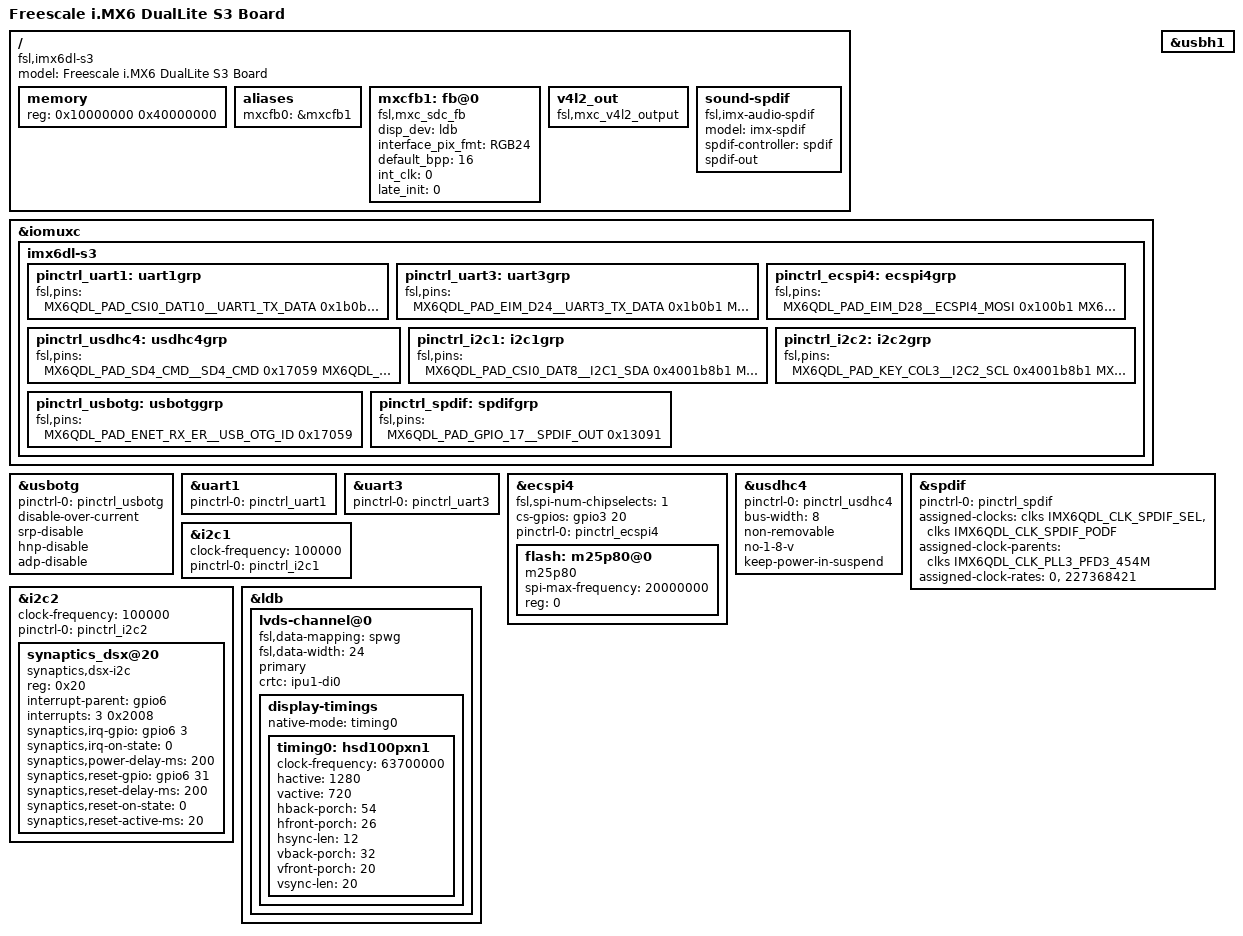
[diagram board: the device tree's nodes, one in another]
/*
 * Copyright (C) 2013 Freescale Semiconductor, Inc.
 *
 * This program is free software; you can redistribute it and/or modify
 * it under the terms of the GNU General Public License version 2 as
 * published by the Free Software Foundation.
 */

/dts-v1/;
#include "imx6dl.dtsi"
#include <dt-bindings/input/input.h>

/ {
	model = "Freescale i.MX6 DualLite S3 Board";
	compatible = "fsl,imx6dl-s3", "fsl,imx6dl";
	memory {
		reg = <0x10000000 0x40000000>;
	};
	
	aliases {
		mxcfb0 = &mxcfb1;
	};	
	mxcfb1: fb@0 {
		compatible = "fsl,mxc_sdc_fb";
		disp_dev = "ldb";
		interface_pix_fmt = "RGB24";
		default_bpp = <16>;
		int_clk = <0>;
		late_init = <0>;
		status = "okay";
	};

	v4l2_out {
		compatible = "fsl,mxc_v4l2_output";
		status = "okay";
	};

	sound-spdif {
		compatible = "fsl,imx-audio-spdif";
		model = "imx-spdif";
		spdif-controller = <&spdif>;
		spdif-out;
	};
};



&iomuxc {
	pinctrl-names = "default";
	
	imx6dl-s3 {
		//debug uart
		pinctrl_uart1: uart1grp {
			fsl,pins = <
				MX6QDL_PAD_CSI0_DAT10__UART1_TX_DATA	0x1b0b1
				MX6QDL_PAD_CSI0_DAT11__UART1_RX_DATA	0x1b0b1
			>;
		};
		//mcu uart
		pinctrl_uart3: uart3grp {
			fsl,pins = <
				MX6QDL_PAD_EIM_D24__UART3_TX_DATA	0x1b0b1
				MX6QDL_PAD_EIM_D25__UART3_RX_DATA	0x1b0b1
			>;
		};
		//spi nor
		pinctrl_ecspi4: ecspi4grp {
			fsl,pins = <
				MX6QDL_PAD_EIM_D28__ECSPI4_MOSI		0x100b1
				MX6QDL_PAD_EIM_D22__ECSPI4_MISO		0x100b1
				MX6QDL_PAD_EIM_D21__ECSPI4_SCLK		0x100b1
				MX6QDL_PAD_EIM_D20__GPIO3_IO20 	     0x80000000
			>;
		};
		//emmc
		pinctrl_usdhc4: usdhc4grp {
			fsl,pins = <
				MX6QDL_PAD_SD4_CMD__SD4_CMD		0x17059
				MX6QDL_PAD_SD4_CLK__SD4_CLK		0x10059
				MX6QDL_PAD_SD4_DAT0__SD4_DATA0		0x17059
				MX6QDL_PAD_SD4_DAT1__SD4_DATA1		0x17059
				MX6QDL_PAD_SD4_DAT2__SD4_DATA2		0x17059
				MX6QDL_PAD_SD4_DAT3__SD4_DATA3		0x17059
				MX6QDL_PAD_SD4_DAT4__SD4_DATA4		0x17059
				MX6QDL_PAD_SD4_DAT5__SD4_DATA5		0x17059
				MX6QDL_PAD_SD4_DAT6__SD4_DATA6		0x17059
				MX6QDL_PAD_SD4_DAT7__SD4_DATA7		0x17059
			>;
		};
		//pmic i2c 
		pinctrl_i2c1: i2c1grp {
			fsl,pins = <
				MX6QDL_PAD_CSI0_DAT8__I2C1_SDA		0x4001b8b1
				MX6QDL_PAD_CSI0_DAT9__I2C1_SCL		0x4001b8b1
			>;
		};
		//touchscreen i2c
		pinctrl_i2c2: i2c2grp {
			fsl,pins = <
				MX6QDL_PAD_KEY_COL3__I2C2_SCL		0x4001b8b1
				MX6QDL_PAD_KEY_ROW3__I2C2_SDA		0x4001b8b1
				MX6QDL_PAD_CSI0_DAT17__GPIO6_IO03       0x80000000
				MX6QDL_PAD_EIM_BCLK__GPIO6_IO31         0x80000000
			 >;
		};

		//USB OTG
		pinctrl_usbotg: usbotggrp {
			fsl,pins = <
				MX6QDL_PAD_ENET_RX_ER__USB_OTG_ID 	0x17059
			>;
		};
		//SPDIF AUDIO OUT
		pinctrl_spdif: spdifgrp {
			fsl,pins = <
				MX6QDL_PAD_GPIO_17__SPDIF_OUT 		0x13091
			>;
		};

	};
};


&usbh1 {
	status = "okay";
};
&usbotg {
	pinctrl-names = "default";
	pinctrl-0 = <&pinctrl_usbotg>;
	disable-over-current;
	srp-disable;
	hnp-disable;
	adp-disable;
	status = "okay";
};

&uart1 {
	pinctrl-names = "default";
	pinctrl-0 = <&pinctrl_uart1>;
	status = "okay";
};

&uart3 {
	pinctrl-names = "default";
	pinctrl-0 = <&pinctrl_uart3>;
	status = "okay";
};

&ecspi4 {
	fsl,spi-num-chipselects = <1>;
	cs-gpios = <&gpio3 20 0>;
	pinctrl-names = "default";
	pinctrl-0 = <&pinctrl_ecspi4>;
	status = "okay";

	flash: m25p80@0 {
		#address-cells = <1>;
		#size-cells = <1>;
		compatible = "m25p80"; //??
		spi-max-frequency = <20000000>;
		reg = <0>;
	};
};

&usdhc4 {
	pinctrl-names = "default";
	pinctrl-0 = <&pinctrl_usdhc4>;
	bus-width = <8>;
	non-removable;
	no-1-8-v;
	keep-power-in-suspend;
	status = "okay";
};

&spdif {
	pinctrl-names = "default";
	pinctrl-0 = <&pinctrl_spdif>;
	assigned-clocks = <&clks IMX6QDL_CLK_SPDIF_SEL>,
					<&clks IMX6QDL_CLK_SPDIF_PODF>;
	assigned-clock-parents = <&clks IMX6QDL_CLK_PLL3_PFD3_454M>;
	assigned-clock-rates = <0>, <227368421>;
	status = "okay";
};

&i2c1 {
	clock-frequency = <100000>;
	pinctrl-names = "default";
	pinctrl-0 = <&pinctrl_i2c1>;
	status = "okay";
};

&i2c2 {
	clock-frequency = <100000>;
	pinctrl-names = "default";
	pinctrl-0 = <&pinctrl_i2c2>;
	status = "okay";

	synaptics_dsx@20 {
		compatible = "synaptics,dsx-i2c";
		reg = <0x20>;
		interrupt-parent = <&gpio6>;
		interrupts = <3 0x2008>;
		/* vdd_ana-supply = <&pm8941_l18>; */
		/* vcc_i2c-supply = <&pm8941_s3>; */
		/* synaptics,pwr-reg-name = "vdd_ana"; */
		/* synaptics,bus-reg-name = "vcc_i2c"; */
		synaptics,irq-gpio = <&gpio6 3 0x2008>; /* IRQF_ONESHOT | IRQF_TRIGGER_LOW */
		synaptics,irq-on-state = <0>;
		synaptics,power-delay-ms = <200>;
		synaptics,reset-gpio = <&gpio6 31 0x0>;
		synaptics,reset-delay-ms = <200>;
		synaptics,reset-on-state = <0>;
		synaptics,reset-active-ms = <20>;
		/* uncomment and update line below as appropriate if there are 0D buttons */
		/* synaptics,cap-button-codes = <102 158>; */
		/* uncomment and update lines below as appropriate if there are virtual buttons */
		/* synaptics,vir-button-codes = <102 100 900 100 60 158 300 900 100 60>; */
		/* synaptics,max-y-for-2d = <800>; */
	};
};

&ldb {
	status = "okay";

	lvds-channel@0 {
		fsl,data-mapping = "spwg";
		fsl,data-width = <24>;
		primary;
		crtc = "ipu1-di0";
		status = "okay";

		display-timings {
			native-mode = <&timing0>;
			timing0: hsd100pxn1 {
				clock-frequency = <63700000>;
				hactive = <1280>;
				vactive = <720>;
				hback-porch = <54>;
				hfront-porch = <26>;
				hsync-len = <12>;
				vback-porch = <32>;
				vfront-porch = <20>;
				vsync-len = <20>;
			};
		};
	};

};
















